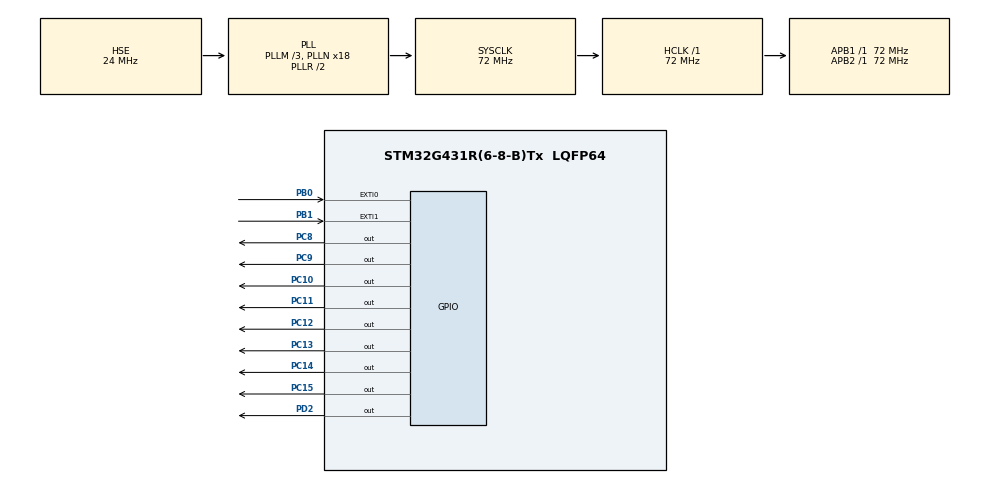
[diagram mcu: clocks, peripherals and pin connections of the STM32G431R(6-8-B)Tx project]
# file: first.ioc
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Mcu.Family=STM32G4
Mcu.Name=STM32G431R(6-8-B)Tx
Mcu.Package=LQFP64
NVIC.EXTI0_IRQn=true\:0\:0\:false\:false\:true\:true\:true
NVIC.EXTI1_IRQn=true\:0\:0\:false\:false\:true\:true\:true
NVIC.PriorityGroup=NVIC_PRIORITYGROUP_4
PA13.Mode=Serial_Wire
PA13.Signal=SYS_JTMS-SWDIO
PA14.Mode=Serial_Wire
PA14.Signal=SYS_JTCK-SWCLK
PB0.GPIO_ModeDefaultEXTI=GPIO_MODE_IT_FALLING
PB0.GPIO_PuPd=GPIO_PULLUP
PB0.Signal=GPXTI0
PB1.GPIO_ModeDefaultEXTI=GPIO_MODE_IT_FALLING
PB1.GPIO_PuPd=GPIO_PULLUP
PB1.Signal=GPXTI1
PC10.PinState=GPIO_PIN_SET
PC10.Signal=GPIO_Output
PC11.PinState=GPIO_PIN_SET
PC11.Signal=GPIO_Output
PC12.PinState=GPIO_PIN_SET
PC12.Signal=GPIO_Output
PC13.PinState=GPIO_PIN_SET
PC13.Signal=GPIO_Output
PC14-OSC32_IN.PinState=GPIO_PIN_SET
PC14-OSC32_IN.Signal=GPIO_Output
PC15-OSC32_OUT.PinState=GPIO_PIN_SET
PC15-OSC32_OUT.Signal=GPIO_Output
PC8.PinState=GPIO_PIN_SET
PC8.Signal=GPIO_Output
PC9.PinState=GPIO_PIN_SET
PC9.Signal=GPIO_Output
PD2.PinState=GPIO_PIN_RESET
PD2.Signal=GPIO_Output
PF0-OSC_IN.Mode=HSE-External-Oscillator
PF0-OSC_IN.Signal=RCC_OSC_IN
PF1-OSC_OUT.Mode=HSE-External-Oscillator
PF1-OSC_OUT.Signal=RCC_OSC_OUT
ProjectManager.HeapSize=0x200
ProjectManager.StackSize=0x400
ProjectManager.TargetToolchain=MDK-ARM V5
RCC.ADC12Freq_Value=72000000
RCC.AHBFreq_Value=72000000
RCC.APB1Freq_Value=72000000
RCC.APB1TimFreq_Value=72000000
RCC.APB2Freq_Value=72000000
RCC.APB2TimFreq_Value=72000000
RCC.CortexFreq_Value=72000000
RCC.EXTERNAL_CLOCK_VALUE=12288000
RCC.HCLKFreq_Value=72000000
RCC.HSE_VALUE=24000000
RCC.HSI48_VALUE=48000000
RCC.HSI_VALUE=16000000
RCC.LSE_VALUE=32768
RCC.PLLM=RCC_PLLM_DIV3
RCC.PLLN=18
RCC.PLLSourceVirtual=RCC_PLLSOURCE_HSE
RCC.SYSCLKFreq_VALUE=72000000
RCC.SYSCLKSource=RCC_SYSCLKSOURCE_PLLCLK
RCC.USBFreq_Value=72000000
RCC.VCOOutputFreq_Value=144000000
VP_SYS_VS_DBSignals.Mode=DisableDeadBatterySignals
board=custom

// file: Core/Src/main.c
/* USER CODE BEGIN Header */
/**
  ******************************************************************************
  * @file           : main.c
  * @brief          : Main program body
  ******************************************************************************
  * @attention
  *
  * <h2><center>&copy; Copyright (c) 2024 STMicroelectronics.
  * All rights reserved.</center></h2>
  *
  * This software component is licensed by ST under BSD 3-Clause license,
  * the "License"; You may not use this file except in compliance with the
  * License. You may obtain a copy of the License at:
  *                        opensource.org/licenses/BSD-3-Clause
  *
  ******************************************************************************
  */
/* USER CODE END Header */

#include "main.h"
#include "gpio.h"

/* USER CODE BEGIN Includes */
#include "stm32g4xx_hal_uart.h"
#include "led.h"
#include "lcd.h"
#include "stdio.h"
/* USER CODE END Includes */

void SystemClock_Config(void);

/* USER CODE BEGIN 0 */

//上位机结合stm32显示画面的串口设置
/*
UART_HandleTypeDef huart1;
uint8_t uart_rx_buf1[1024 * 6]; //串口接收数据缓冲区1
uint8_t uart_rx_buf2[1024 * 6]; //串口接收数据缓冲区2

// UART1 初始化
static void MX_UART1_Init(void)
{
	GPIO_InitTypeDef GPIO_InitStruct = {0};
	RCC_PeriphCLKInitTypeDef PeriphClkInit = {0};

	PeriphClkInit.PeriphClockSelection = RCC_PERIPHCLK_USART1;
	PeriphClkInit.Usart1ClockSelection = RCC_USART1CLKSOURCE_PCLK2;
	HAL_RCCEx_PeriphCLKConfig(&PeriphClkInit); //配置USART1外设的时钟

	__HAL_RCC_USART1_CLK_ENABLE(); //打开USART1的时钟
	__HAL_RCC_GPIOA_CLK_ENABLE();

	huart1.Instance = USART1;
	huart1.Init.BaudRate = 1000000; //设置波特率
	huart1.Init.WordLength = UART_WORDLENGTH_8B; //设置数据位
	huart1.Init.StopBits = UART_STOPBITS_1; //设置停止位
	huart1.Init.Parity = UART_PARITY_NONE;
	huart1.Init.Mode = UART_MODE_TX_RX;
	huart1.Init.HwFlowCtl = UART_HWCONTROL_NONE;
	huart1.Init.OverSampling = UART_OVERSAMPLING_16;
	huart1.Init.OneBitSampling = UART_ONE_BIT_SAMPLE_DISABLE;
	huart1.Init.ClockPrescaler = UART_PRESCALER_DIV1;
	huart1.AdvancedInit.AdvFeatureInit = UART_ADVFEATURE_NO_INIT;

	HAL_MultiProcessor_Init(&huart1, 0, UART_WAKEUPMETHOD_IDLELINE);
	HAL_UARTEx_SetTxFifoThreshold(&huart1, UART_TXFIFO_THRESHOLD_1_8);

	HAL_UARTEx_SetRxFifoThreshold(&huart1, UART_RXFIFO_THRESHOLD_1_8);
	HAL_UARTEx_DisableFifoMode(&huart1);

	GPIO_InitStruct.Pin = GPIO_PIN_9|GPIO_PIN_10;
	GPIO_InitStruct.Mode = GPIO_MODE_AF_OD; //复用开漏输出
	GPIO_InitStruct.Pull = GPIO_NOPULL;
	GPIO_InitStruct.Speed = GPIO_SPEED_FREQ_LOW;
	GPIO_InitStruct.Alternate = GPIO_AF7_USART1;//复用功能
	HAL_GPIO_Init(GPIOA, &GPIO_InitStruct); //初始化串口引脚PA9 PA10

	HAL_NVIC_SetPriority(USART1_IRQn, 0, 0); //设置串口中断优先级
	HAL_NVIC_EnableIRQ(USART1_IRQn); //打开串口中断

	HAL_UART_Receive_IT(&huart1, uart_rx_buf1, 4800); //设置串口中断缓冲区及中断阈值(当前为1)
}

//串口中断
void USART1_IRQHandler(void) //串口中断
{
	HAL_UART_IRQHandler(&huart1);
}
int buf = 1; //记录当前使用的是buf1 还是 buf2
int disp = 0; //告诉main该显示什么内容，0不显示，1显示buf1，2显示buf2

//串口中断回调函数
void HAL_UART_RxCpltCallback(UART_HandleTypeDef *huart)
{
	if(buf == 1) //若果当前是使用的是buf1
	{
		buf = 2; //下次使用buf2
		disp = 1;//告诉main显示buf1的内容到屏幕
		HAL_UART_Receive_IT(&huart1, uart_rx_buf2, 4800);  //切换为buf2
	}
	else
	{
		buf = 1; //下次使用buf1
		disp = 2;//告诉main显示buf2的内容到屏幕
		HAL_UART_Receive_IT(&huart1, uart_rx_buf1, 4800);  //切换为buf2
	}
}
*/

void HAL_GPIO_EXTI_Callback(uint16_t GPIO_Pin)
{

	if(GPIO_Pin==GPIO_PIN_0)
	{

		HAL_GPIO_TogglePin(GPIOC,GPIO_PIN_15);
	}
  else if(GPIO_Pin==GPIO_PIN_1)
	{

		HAL_GPIO_TogglePin(GPIOC,GPIO_PIN_8);
	}

}

/* USER CODE END 0 */

int main(void)
{

  /* MCU Configuration--------------------------------------------------------*/

  /* Reset of all peripherals, Initializes the Flash interface and the Systick. */
  HAL_Init();

  /* Configure the system clock */
  SystemClock_Config();

  /* Initialize all configured peripherals */
  MX_GPIO_Init();
  /* USER CODE BEGIN 2 */

	//LED_Display(0x00);			//led初始化
	LCD_Init();			//lcd初始化

	//清空背景为蓝色
	LCD_Clear(Black);
	//设置背景色为蓝色
	LCD_SetBackColor(Black);
	//设置前景色为白色
	LCD_SetTextColor(White);

	/*
	//将界面划分为四小格
	LCD_DrawLine(120,0,320,Horizontal);
	LCD_DrawLine(0,160,240,Vertical);
	HAL_Delay(1000);
	LCD_Clear(Blue);

	//在界面中心显示一个矩形
	LCD_DrawRect(70,210,100,100);
	HAL_Delay(1000);
	LCD_Clear(Blue);

	//在界面中心显示一个圆形
	LCD_DrawCircle(120,160,50);
	HAL_Delay(1000);

	//清空LCD背景为蓝色
	LCD_Clear(Blue);
	LCD_DisplayStringLine(Line4 ,(unsigned char *)"    Hello,world.   ");
	HAL_Delay(1000);

	LCD_SetBackColor(White);
	LCD_DisplayStringLine(Line0,(unsigned char *)"                    ");
	LCD_SetBackColor(Black);
	LCD_DisplayStringLine(Line1,(unsigned char *)"                    ");
	LCD_SetBackColor(Grey);
	LCD_DisplayStringLine(Line2,(unsigned char *)"                    ");
	LCD_SetBackColor(Blue);
	LCD_DisplayStringLine(Line3,(unsigned char *)"                    ");
	LCD_SetBackColor(Blue2);
	LCD_DisplayStringLine(Line4,(unsigned char *)"                    ");
	LCD_SetBackColor(Red);
	LCD_DisplayStringLine(Line5,(unsigned char *)"                    ");
	LCD_SetBackColor(Magenta);
	LCD_DisplayStringLine(Line6,(unsigned char *)"                    ");
	LCD_SetBackColor(Green);
	LCD_DisplayStringLine(Line7,(unsigned char *)"                    ");
	LCD_SetBackColor(Cyan);
	LCD_DisplayStringLine(Line8,(unsigned char *)"                    ");
	LCD_SetBackColor(Yellow);
	LCD_DisplayStringLine(Line9,(unsigned char *)"                    ");
	*/

  /* USER CODE END 2 */

  /* Infinite loop */
  while (1)
  {

  }
}

void SystemClock_Config(void)
{
  RCC_OscInitTypeDef RCC_OscInitStruct = {0};
  RCC_ClkInitTypeDef RCC_ClkInitStruct = {0};

  /** Configure the main internal regulator output voltage
  */
  HAL_PWREx_ControlVoltageScaling(PWR_REGULATOR_VOLTAGE_SCALE1);
  /** Initializes the CPU, AHB and APB busses clocks
  */
  RCC_OscInitStruct.OscillatorType = RCC_OSCILLATORTYPE_HSE;
  RCC_OscInitStruct.HSEState = RCC_HSE_ON;
  RCC_OscInitStruct.PLL.PLLState = RCC_PLL_ON;
  RCC_OscInitStruct.PLL.PLLSource = RCC_PLLSOURCE_HSE;
  RCC_OscInitStruct.PLL.PLLM = RCC_PLLM_DIV3;
  RCC_OscInitStruct.PLL.PLLN = 18;
  RCC_OscInitStruct.PLL.PLLP = RCC_PLLP_DIV2;
  RCC_OscInitStruct.PLL.PLLQ = RCC_PLLQ_DIV2;
  RCC_OscInitStruct.PLL.PLLR = RCC_PLLR_DIV2;
  if (HAL_RCC_OscConfig(&RCC_OscInitStruct) != HAL_OK)
  {
    Error_Handler();
  }
  /** Initializes the CPU, AHB and APB busses clocks
  */
  RCC_ClkInitStruct.ClockType = RCC_CLOCKTYPE_HCLK|RCC_CLOCKTYPE_SYSCLK
                              |RCC_CLOCKTYPE_PCLK1|RCC_CLOCKTYPE_PCLK2;
  RCC_ClkInitStruct.SYSCLKSource = RCC_SYSCLKSOURCE_PLLCLK;
  RCC_ClkInitStruct.AHBCLKDivider = RCC_SYSCLK_DIV1;
  RCC_ClkInitStruct.APB1CLKDivider = RCC_HCLK_DIV1;
  RCC_ClkInitStruct.APB2CLKDivider = RCC_HCLK_DIV1;

  if (HAL_RCC_ClockConfig(&RCC_ClkInitStruct, FLASH_LATENCY_3) != HAL_OK)
  {
    Error_Handler();
  }
}

void Error_Handler(void)
{
}

/************************ (C) COPYRIGHT STMicroelectronics *****END OF FILE****/
